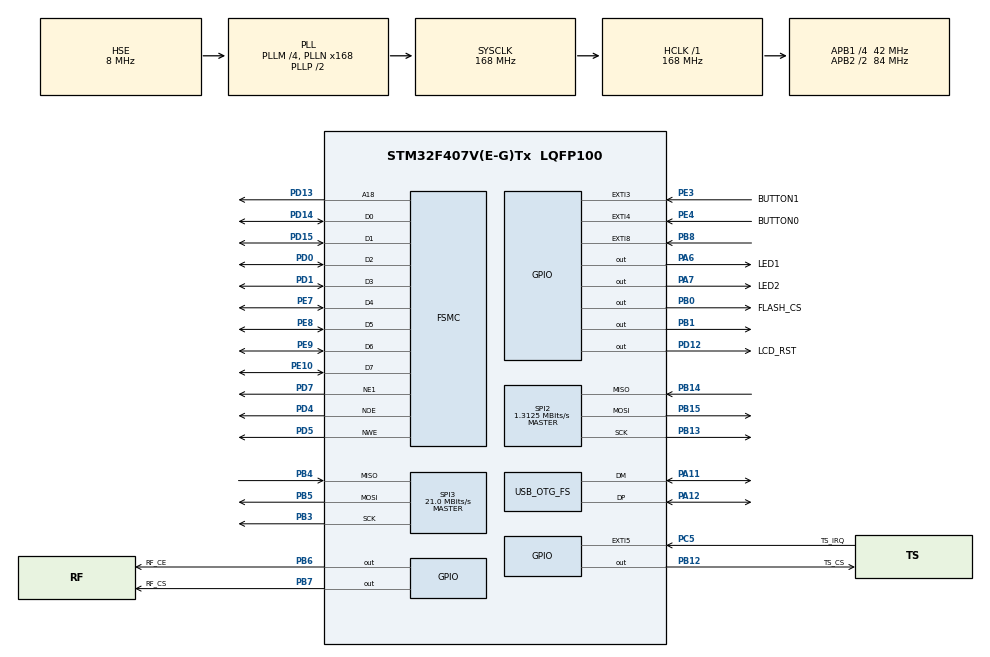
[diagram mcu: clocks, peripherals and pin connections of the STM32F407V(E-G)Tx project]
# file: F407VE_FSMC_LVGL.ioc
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Dma.MEMTOMEM.0.Direction=DMA_MEMORY_TO_MEMORY
Dma.MEMTOMEM.0.FIFOMode=DMA_FIFOMODE_ENABLE
Dma.MEMTOMEM.0.FIFOThreshold=DMA_FIFO_THRESHOLD_FULL
Dma.MEMTOMEM.0.Instance=DMA2_Stream0
Dma.MEMTOMEM.0.MemBurst=DMA_MBURST_SINGLE
Dma.MEMTOMEM.0.MemDataAlignment=DMA_MDATAALIGN_BYTE
Dma.MEMTOMEM.0.MemInc=DMA_MINC_DISABLE
Dma.MEMTOMEM.0.Mode=DMA_NORMAL
Dma.MEMTOMEM.0.PeriphBurst=DMA_PBURST_SINGLE
Dma.MEMTOMEM.0.PeriphDataAlignment=DMA_PDATAALIGN_HALFWORD
Dma.MEMTOMEM.0.PeriphInc=DMA_PINC_ENABLE
Dma.MEMTOMEM.0.Priority=DMA_PRIORITY_VERY_HIGH
Dma.Request0=MEMTOMEM
FSMC.AddressSetupTime1=2
FSMC.BusTurnAroundDuration1=1
FSMC.DataSetupTime1=2
Mcu.Family=STM32F4
Mcu.Name=STM32F407V(E-G)Tx
Mcu.Package=LQFP100
NVIC.DMA2_Stream0_IRQn=true\:0\:0\:false\:false\:true\:true\:true\:true
NVIC.EXTI3_IRQn=true\:0\:0\:false\:false\:true\:true\:true\:true
NVIC.EXTI4_IRQn=true\:0\:0\:false\:false\:true\:true\:true\:true
NVIC.EXTI9_5_IRQn=true\:0\:0\:false\:false\:true\:true\:true\:true
NVIC.HASH_RNG_IRQn=true\:0\:0\:false\:false\:true\:true\:true\:true
NVIC.OTG_FS_IRQn=true\:0\:0\:false\:false\:true\:true\:true\:true
NVIC.PriorityGroup=NVIC_PRIORITYGROUP_4
PA0-WKUP.Mode=SYS_WakeUp0
PA0-WKUP.Signal=SYS_WKUP
PA11.Mode=Device_Only
PA11.Signal=USB_OTG_FS_DM
PA12.Mode=Device_Only
PA12.Signal=USB_OTG_FS_DP
PA13.Mode=Serial_Wire
PA13.Signal=SYS_JTMS-SWDIO
PA14.Mode=Serial_Wire
PA14.Signal=SYS_JTCK-SWCLK
PA6.GPIO_Label=LED1
PA6.PinState=GPIO_PIN_SET
PA6.Signal=GPIO_Output
PA7.GPIO_Label=LED2
PA7.PinState=GPIO_PIN_SET
PA7.Signal=GPIO_Output
PB0.GPIO_Label=FLASH_CS
PB0.GPIO_Speed=GPIO_SPEED_FREQ_HIGH
PB0.Signal=GPIO_Output
PB1.Signal=GPIO_Output
PB12.GPIO_Label=TS_CS
PB12.GPIO_PuPd=GPIO_PULLUP
PB12.GPIO_Speed=GPIO_SPEED_FREQ_HIGH
PB12.PinState=GPIO_PIN_SET
PB12.Signal=GPIO_Output
PB13.Mode=Full_Duplex_Master
PB13.Signal=SPI2_SCK
PB14.Mode=Full_Duplex_Master
PB14.Signal=SPI2_MISO
PB15.Mode=Full_Duplex_Master
PB15.Signal=SPI2_MOSI
PB3.Mode=Full_Duplex_Master
PB3.Signal=SPI3_SCK
PB4.Mode=Full_Duplex_Master
PB4.Signal=SPI3_MISO
PB5.Mode=Full_Duplex_Master
PB5.Signal=SPI3_MOSI
PB6.GPIO_Label=RF_CE
PB6.GPIO_Speed=GPIO_SPEED_FREQ_HIGH
PB6.Signal=GPIO_Output
PB7.GPIO_Label=RF_CS
PB7.GPIO_Speed=GPIO_SPEED_FREQ_HIGH
PB7.PinState=GPIO_PIN_RESET
PB7.Signal=GPIO_Output
PB8.GPIO_PuPd=GPIO_PULLUP
PB8.Signal=GPXTI8
PC14-OSC32_IN.Mode=LSE-External-Oscillator
PC14-OSC32_IN.Signal=RCC_OSC32_IN
PC15-OSC32_OUT.Mode=LSE-External-Oscillator
PC15-OSC32_OUT.Signal=RCC_OSC32_OUT
PC5.GPIO_Label=TS_IRQ
PC5.GPIO_PuPd=GPIO_PULLUP
PC5.Signal=GPXTI5
PD0.Mode=8b-d1
PD0.Signal=FSMC_D2
PD1.Mode=8b-d1
PD1.Signal=FSMC_D3
PD12.GPIO_Label=LCD_RST
PD12.Signal=GPIO_Output
PD13.Mode=A18_1
PD13.Signal=FSMC_A18
PD14.Mode=8b-d1
PD14.Signal=FSMC_D0
PD15.Mode=8b-d1
PD15.Signal=FSMC_D1
PD4.Mode=Lcd1
PD4.Signal=FSMC_NOE
PD5.Mode=Lcd1
PD5.Signal=FSMC_NWE
PD7.Mode=NorPsramChipSelect1_1
PD7.Signal=FSMC_NE1
PE10.Mode=8b-d1
PE10.Signal=FSMC_D7
PE3.GPIO_Label=BUTTON1
PE3.GPIO_PuPd=GPIO_PULLUP
PE3.Signal=GPXTI3
PE4.GPIO_Label=BUTTON0
PE4.GPIO_PuPd=GPIO_PULLUP
PE4.Signal=GPXTI4
PE7.Mode=8b-d1
PE7.Signal=FSMC_D4
PE8.Mode=8b-d1
PE8.Signal=FSMC_D5
PE9.Mode=8b-d1
PE9.Signal=FSMC_D6
PH0-OSC_IN.Mode=HSE-External-Oscillator
PH0-OSC_IN.Signal=RCC_OSC_IN
PH1-OSC_OUT.Mode=HSE-External-Oscillator
PH1-OSC_OUT.Signal=RCC_OSC_OUT
ProjectManager.HeapSize=0x2000
ProjectManager.StackSize=0x2000
ProjectManager.TargetToolchain=STM32CubeIDE
RCC.48MHZClocksFreq_Value=48000000
RCC.AHBFreq_Value=168000000
RCC.APB1CLKDivider=RCC_HCLK_DIV4
RCC.APB1Freq_Value=42000000
RCC.APB1TimFreq_Value=84000000
RCC.APB2CLKDivider=RCC_HCLK_DIV2
RCC.APB2Freq_Value=84000000
RCC.APB2TimFreq_Value=168000000
RCC.CortexFreq_Value=168000000
RCC.HCLKFreq_Value=168000000
RCC.HSE_VALUE=8000000
RCC.HSICalibrationValue=8
RCC.HSI_VALUE=16000000
RCC.PLLM=4
RCC.PLLN=168
RCC.PLLQ=7
RCC.SYSCLKFreq_VALUE=168000000
RCC.SYSCLKSource=RCC_SYSCLKSOURCE_PLLCLK
RCC.VCOOutputFreq_Value=336000000
SPI2.BaudRatePrescaler=SPI_BAUDRATEPRESCALER_32
SPI2.CalculateBaudRate=1.3125 MBits/s
SPI2.Direction=SPI_DIRECTION_2LINES
SPI2.Mode=SPI_MODE_MASTER
SPI2.VirtualType=VM_MASTER
SPI3.CalculateBaudRate=21.0 MBits/s
SPI3.Direction=SPI_DIRECTION_2LINES
SPI3.Mode=SPI_MODE_MASTER
SPI3.VirtualType=VM_MASTER
USB_DEVICE.CLASS_NAME_FS=MSC
USB_DEVICE.VirtualMode-MSC_FS=Msc
USB_DEVICE.VirtualModeFS=Msc_FS
USB_OTG_FS.VirtualMode=Device_Only
VP_RNG_VS_RNG.Mode=RNG_Activate
VP_USB_DEVICE_VS_USB_DEVICE_MSC_FS.Mode=MSC_FS
board=custom

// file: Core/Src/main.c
/* USER CODE BEGIN Header */
/*******************************************************************************
Created by profi-max (Oleg Linnik) 2024
https://profimaxblog.ru
https://github.com/profi-max

*******************************************************************************/
/**

//=============================================================================
//		8-bit parallel LCD R61581 / no touch for LVGL version 8.3.10
//=============================================================================

  ******************************************************************************
  */
/* USER CODE END Header */
#include "main.h"
#include "usb_device.h"

/* USER CODE BEGIN Includes */
#include "../lvgl/lvgl.h"
#include "../lvgl/examples/lv_examples.h"
#include "lcd_lvgl.h"
/* USER CODE END Includes */

RNG_HandleTypeDef hrng;

SPI_HandleTypeDef hspi2;
SPI_HandleTypeDef hspi3;

DMA_HandleTypeDef hdma_memtomem_dma2_stream0;
SRAM_HandleTypeDef hsram1;

void SystemClock_Config(void);
static void MX_GPIO_Init(void);
static void MX_DMA_Init(void);
static void MX_FSMC_Init(void);
static void MX_RNG_Init(void);
static void MX_SPI2_Init(void);
static void MX_SPI3_Init(void);

int main(void)
{

  /* MCU Configuration--------------------------------------------------------*/

  /* Reset of all peripherals, Initializes the Flash interface and the Systick. */
  HAL_Init();

  /* Configure the system clock */
  SystemClock_Config();

  /* Initialize all configured peripherals */
  MX_GPIO_Init();
  MX_DMA_Init();
  MX_FSMC_Init();
  MX_RNG_Init();
  MX_SPI2_Init();
  MX_USB_DEVICE_Init();
  MX_SPI3_Init();
  /* USER CODE BEGIN 2 */

    LVGL_setup();
    lv_demo_benchmark_set_max_speed(true);
    lv_demo_benchmark();
//    lv_demo_widgets();
//    lv_example_meter_4();
//    lv_example_chart_1();
  /* USER CODE END 2 */

  /* Infinite loop */
  while (1)
  {

    /* USER CODE BEGIN 3 */
	  lv_task_handler();
	  HAL_Delay(5);

  }
  /* USER CODE END 3 */
}

void SystemClock_Config(void)
{
  RCC_OscInitTypeDef RCC_OscInitStruct = {0};
  RCC_ClkInitTypeDef RCC_ClkInitStruct = {0};

  /** Configure the main internal regulator output voltage
  */
  __HAL_RCC_PWR_CLK_ENABLE();
  __HAL_PWR_VOLTAGESCALING_CONFIG(PWR_REGULATOR_VOLTAGE_SCALE1);

  /** Initializes the RCC Oscillators according to the specified parameters
  * in the RCC_OscInitTypeDef structure.
  */
  RCC_OscInitStruct.OscillatorType = RCC_OSCILLATORTYPE_HSE;
  RCC_OscInitStruct.HSEState = RCC_HSE_ON;
  RCC_OscInitStruct.PLL.PLLState = RCC_PLL_ON;
  RCC_OscInitStruct.PLL.PLLSource = RCC_PLLSOURCE_HSE;
  RCC_OscInitStruct.PLL.PLLM = 4;
  RCC_OscInitStruct.PLL.PLLN = 168;
  RCC_OscInitStruct.PLL.PLLP = RCC_PLLP_DIV2;
  RCC_OscInitStruct.PLL.PLLQ = 7;
  if (HAL_RCC_OscConfig(&RCC_OscInitStruct) != HAL_OK)
  {
    Error_Handler();
  }

  /** Initializes the CPU, AHB and APB buses clocks
  */
  RCC_ClkInitStruct.ClockType = RCC_CLOCKTYPE_HCLK|RCC_CLOCKTYPE_SYSCLK
                              |RCC_CLOCKTYPE_PCLK1|RCC_CLOCKTYPE_PCLK2;
  RCC_ClkInitStruct.SYSCLKSource = RCC_SYSCLKSOURCE_PLLCLK;
  RCC_ClkInitStruct.AHBCLKDivider = RCC_SYSCLK_DIV1;
  RCC_ClkInitStruct.APB1CLKDivider = RCC_HCLK_DIV4;
  RCC_ClkInitStruct.APB2CLKDivider = RCC_HCLK_DIV2;

  if (HAL_RCC_ClockConfig(&RCC_ClkInitStruct, FLASH_LATENCY_5) != HAL_OK)
  {
    Error_Handler();
  }
}

static void MX_RNG_Init(void)
{

  hrng.Instance = RNG;
  if (HAL_RNG_Init(&hrng) != HAL_OK)
  {
    Error_Handler();
  }

}

static void MX_SPI2_Init(void)
{

  /* SPI2 parameter configuration*/
  hspi2.Instance = SPI2;
  hspi2.Init.Mode = SPI_MODE_MASTER;
  hspi2.Init.Direction = SPI_DIRECTION_2LINES;
  hspi2.Init.DataSize = SPI_DATASIZE_8BIT;
  hspi2.Init.CLKPolarity = SPI_POLARITY_LOW;
  hspi2.Init.CLKPhase = SPI_PHASE_1EDGE;
  hspi2.Init.NSS = SPI_NSS_SOFT;
  hspi2.Init.BaudRatePrescaler = SPI_BAUDRATEPRESCALER_32;
  hspi2.Init.FirstBit = SPI_FIRSTBIT_MSB;
  hspi2.Init.TIMode = SPI_TIMODE_DISABLE;
  hspi2.Init.CRCCalculation = SPI_CRCCALCULATION_DISABLE;
  hspi2.Init.CRCPolynomial = 10;
  if (HAL_SPI_Init(&hspi2) != HAL_OK)
  {
    Error_Handler();
  }

}

static void MX_SPI3_Init(void)
{

  /* SPI3 parameter configuration*/
  hspi3.Instance = SPI3;
  hspi3.Init.Mode = SPI_MODE_MASTER;
  hspi3.Init.Direction = SPI_DIRECTION_2LINES;
  hspi3.Init.DataSize = SPI_DATASIZE_8BIT;
  hspi3.Init.CLKPolarity = SPI_POLARITY_LOW;
  hspi3.Init.CLKPhase = SPI_PHASE_1EDGE;
  hspi3.Init.NSS = SPI_NSS_SOFT;
  hspi3.Init.BaudRatePrescaler = SPI_BAUDRATEPRESCALER_2;
  hspi3.Init.FirstBit = SPI_FIRSTBIT_MSB;
  hspi3.Init.TIMode = SPI_TIMODE_DISABLE;
  hspi3.Init.CRCCalculation = SPI_CRCCALCULATION_DISABLE;
  hspi3.Init.CRCPolynomial = 10;
  if (HAL_SPI_Init(&hspi3) != HAL_OK)
  {
    Error_Handler();
  }

}

static void MX_DMA_Init(void)
{

  /* DMA controller clock enable */
  __HAL_RCC_DMA2_CLK_ENABLE();

  /* Configure DMA request hdma_memtomem_dma2_stream0 on DMA2_Stream0 */
  hdma_memtomem_dma2_stream0.Instance = DMA2_Stream0;
  hdma_memtomem_dma2_stream0.Init.Channel = DMA_CHANNEL_0;
  hdma_memtomem_dma2_stream0.Init.Direction = DMA_MEMORY_TO_MEMORY;
  hdma_memtomem_dma2_stream0.Init.PeriphInc = DMA_PINC_ENABLE;
  hdma_memtomem_dma2_stream0.Init.MemInc = DMA_MINC_DISABLE;
  hdma_memtomem_dma2_stream0.Init.PeriphDataAlignment = DMA_PDATAALIGN_HALFWORD;
  hdma_memtomem_dma2_stream0.Init.MemDataAlignment = DMA_MDATAALIGN_BYTE;
  hdma_memtomem_dma2_stream0.Init.Mode = DMA_NORMAL;
  hdma_memtomem_dma2_stream0.Init.Priority = DMA_PRIORITY_VERY_HIGH;
  hdma_memtomem_dma2_stream0.Init.FIFOMode = DMA_FIFOMODE_ENABLE;
  hdma_memtomem_dma2_stream0.Init.FIFOThreshold = DMA_FIFO_THRESHOLD_FULL;
  hdma_memtomem_dma2_stream0.Init.MemBurst = DMA_MBURST_SINGLE;
  hdma_memtomem_dma2_stream0.Init.PeriphBurst = DMA_PBURST_SINGLE;
  if (HAL_DMA_Init(&hdma_memtomem_dma2_stream0) != HAL_OK)
  {
    Error_Handler( );
  }

  /* DMA interrupt init */
  /* DMA2_Stream0_IRQn interrupt configuration */
  HAL_NVIC_SetPriority(DMA2_Stream0_IRQn, 0, 0);
  HAL_NVIC_EnableIRQ(DMA2_Stream0_IRQn);

}

static void MX_GPIO_Init(void)
{
  GPIO_InitTypeDef GPIO_InitStruct = {0};

  /* GPIO Ports Clock Enable */
  __HAL_RCC_GPIOE_CLK_ENABLE();
  __HAL_RCC_GPIOC_CLK_ENABLE();
  __HAL_RCC_GPIOH_CLK_ENABLE();
  __HAL_RCC_GPIOA_CLK_ENABLE();
  __HAL_RCC_GPIOB_CLK_ENABLE();
  __HAL_RCC_GPIOD_CLK_ENABLE();

  /*Configure GPIO pin Output Level */
  HAL_GPIO_WritePin(GPIOA, LED1_Pin|LED2_Pin, GPIO_PIN_SET);

  /*Configure GPIO pin Output Level */
  HAL_GPIO_WritePin(GPIOB, FLASH_CS_Pin|GPIO_PIN_1|RF_CE_Pin|RF_CS_Pin, GPIO_PIN_RESET);

  /*Configure GPIO pin Output Level */
  HAL_GPIO_WritePin(TS_CS_GPIO_Port, TS_CS_Pin, GPIO_PIN_SET);

  /*Configure GPIO pin Output Level */
  HAL_GPIO_WritePin(LCD_RST_GPIO_Port, LCD_RST_Pin, GPIO_PIN_RESET);

  /*Configure GPIO pins : BUTTON1_Pin BUTTON0_Pin */
  GPIO_InitStruct.Pin = BUTTON1_Pin|BUTTON0_Pin;
  GPIO_InitStruct.Mode = GPIO_MODE_IT_RISING;
  GPIO_InitStruct.Pull = GPIO_PULLUP;
  HAL_GPIO_Init(GPIOE, &GPIO_InitStruct);

  /*Configure GPIO pins : LED1_Pin LED2_Pin */
  GPIO_InitStruct.Pin = LED1_Pin|LED2_Pin;
  GPIO_InitStruct.Mode = GPIO_MODE_OUTPUT_PP;
  GPIO_InitStruct.Pull = GPIO_NOPULL;
  GPIO_InitStruct.Speed = GPIO_SPEED_FREQ_LOW;
  HAL_GPIO_Init(GPIOA, &GPIO_InitStruct);

  /*Configure GPIO pin : TS_IRQ_Pin */
  GPIO_InitStruct.Pin = TS_IRQ_Pin;
  GPIO_InitStruct.Mode = GPIO_MODE_IT_RISING;
  GPIO_InitStruct.Pull = GPIO_PULLUP;
  HAL_GPIO_Init(TS_IRQ_GPIO_Port, &GPIO_InitStruct);

  /*Configure GPIO pins : FLASH_CS_Pin RF_CE_Pin RF_CS_Pin */
  GPIO_InitStruct.Pin = FLASH_CS_Pin|RF_CE_Pin|RF_CS_Pin;
  GPIO_InitStruct.Mode = GPIO_MODE_OUTPUT_PP;
  GPIO_InitStruct.Pull = GPIO_NOPULL;
  GPIO_InitStruct.Speed = GPIO_SPEED_FREQ_HIGH;
  HAL_GPIO_Init(GPIOB, &GPIO_InitStruct);

  /*Configure GPIO pin : PB1 */
  GPIO_InitStruct.Pin = GPIO_PIN_1;
  GPIO_InitStruct.Mode = GPIO_MODE_OUTPUT_PP;
  GPIO_InitStruct.Pull = GPIO_NOPULL;
  GPIO_InitStruct.Speed = GPIO_SPEED_FREQ_LOW;
  HAL_GPIO_Init(GPIOB, &GPIO_InitStruct);

  /*Configure GPIO pin : TS_CS_Pin */
  GPIO_InitStruct.Pin = TS_CS_Pin;
  GPIO_InitStruct.Mode = GPIO_MODE_OUTPUT_PP;
  GPIO_InitStruct.Pull = GPIO_PULLUP;
  GPIO_InitStruct.Speed = GPIO_SPEED_FREQ_HIGH;
  HAL_GPIO_Init(TS_CS_GPIO_Port, &GPIO_InitStruct);

  /*Configure GPIO pin : LCD_RST_Pin */
  GPIO_InitStruct.Pin = LCD_RST_Pin;
  GPIO_InitStruct.Mode = GPIO_MODE_OUTPUT_PP;
  GPIO_InitStruct.Pull = GPIO_NOPULL;
  GPIO_InitStruct.Speed = GPIO_SPEED_FREQ_LOW;
  HAL_GPIO_Init(LCD_RST_GPIO_Port, &GPIO_InitStruct);

  /*Configure GPIO pin : PB8 */
  GPIO_InitStruct.Pin = GPIO_PIN_8;
  GPIO_InitStruct.Mode = GPIO_MODE_IT_RISING;
  GPIO_InitStruct.Pull = GPIO_PULLUP;
  HAL_GPIO_Init(GPIOB, &GPIO_InitStruct);

  /* EXTI interrupt init*/
  HAL_NVIC_SetPriority(EXTI3_IRQn, 0, 0);
  HAL_NVIC_EnableIRQ(EXTI3_IRQn);

  HAL_NVIC_SetPriority(EXTI4_IRQn, 0, 0);
  HAL_NVIC_EnableIRQ(EXTI4_IRQn);

  HAL_NVIC_SetPriority(EXTI9_5_IRQn, 0, 0);
  HAL_NVIC_EnableIRQ(EXTI9_5_IRQn);

}

/* FSMC initialization function */
static void MX_FSMC_Init(void)
{

  FSMC_NORSRAM_TimingTypeDef Timing = {0};

  /** Perform the SRAM1 memory initialization sequence
  */
  hsram1.Instance = FSMC_NORSRAM_DEVICE;
  hsram1.Extended = FSMC_NORSRAM_EXTENDED_DEVICE;
  /* hsram1.Init */
  hsram1.Init.NSBank = FSMC_NORSRAM_BANK1;
  hsram1.Init.DataAddressMux = FSMC_DATA_ADDRESS_MUX_DISABLE;
  hsram1.Init.MemoryType = FSMC_MEMORY_TYPE_SRAM;
  hsram1.Init.MemoryDataWidth = FSMC_NORSRAM_MEM_BUS_WIDTH_8;
  hsram1.Init.BurstAccessMode = FSMC_BURST_ACCESS_MODE_DISABLE;
  hsram1.Init.WaitSignalPolarity = FSMC_WAIT_SIGNAL_POLARITY_LOW;
  hsram1.Init.WrapMode = FSMC_WRAP_MODE_DISABLE;
  hsram1.Init.WaitSignalActive = FSMC_WAIT_TIMING_BEFORE_WS;
  hsram1.Init.WriteOperation = FSMC_WRITE_OPERATION_ENABLE;
  hsram1.Init.WaitSignal = FSMC_WAIT_SIGNAL_DISABLE;
  hsram1.Init.ExtendedMode = FSMC_EXTENDED_MODE_DISABLE;
  hsram1.Init.AsynchronousWait = FSMC_ASYNCHRONOUS_WAIT_DISABLE;
  hsram1.Init.WriteBurst = FSMC_WRITE_BURST_DISABLE;
  hsram1.Init.PageSize = FSMC_PAGE_SIZE_NONE;
  /* Timing */
  Timing.AddressSetupTime = 2;
  Timing.AddressHoldTime = 15;
  Timing.DataSetupTime = 2;
  Timing.BusTurnAroundDuration = 1;
  Timing.CLKDivision = 16;
  Timing.DataLatency = 17;
  Timing.AccessMode = FSMC_ACCESS_MODE_A;
  /* ExtTiming */

  if (HAL_SRAM_Init(&hsram1, &Timing, NULL) != HAL_OK)
  {
    Error_Handler( );
  }

}

void Error_Handler(void)
{
  __disable_irq();
  while (1)
  {
  }
}
